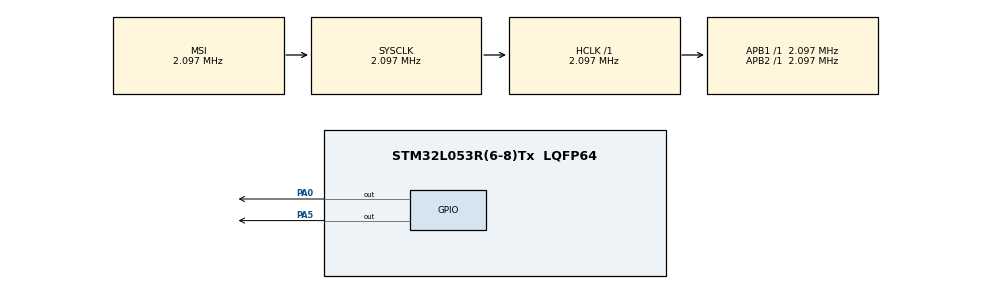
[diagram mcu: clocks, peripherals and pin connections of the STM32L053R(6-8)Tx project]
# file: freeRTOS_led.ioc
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FREERTOS.Tasks01=defaultTask,24,128,StartDefaultTask,Default,NULL,Dynamic,NULL,NULL
Mcu.Family=STM32L0
Mcu.Name=STM32L053R(6-8)Tx
Mcu.Package=LQFP64
PA0.Signal=GPIO_Output
PA5.Signal=GPIO_Output
ProjectManager.HeapSize=0x200
ProjectManager.StackSize=0x400
ProjectManager.TargetToolchain=STM32CubeIDE
RCC.AHBFreq_Value=2097000
RCC.APB1Freq_Value=2097000
RCC.APB1TimFreq_Value=2097000
RCC.APB2Freq_Value=2097000
RCC.APB2TimFreq_Value=2097000
RCC.HSE_VALUE=8000000
RCC.HSI16_VALUE=16000000
RCC.HSI48_VALUE=48000000
RCC.HSI_VALUE=16000000
RCC.LSE_VALUE=32768
RCC.MSI_VALUE=2097000
RCC.SYSCLKFreq_VALUE=2097000
RCC.VCOOutputFreq_Value=48000000
VP_FREERTOS_VS_CMSIS_V2.Mode=CMSIS_V2
board=custom

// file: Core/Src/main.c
/* USER CODE BEGIN Header */
/**
  ******************************************************************************
  * @file           : main.c
  * @brief          : Main program body
  ******************************************************************************
  * @attention
  *
  * Copyright (c) 2023 STMicroelectronics.
  * All rights reserved.
  *
  * This software is licensed under terms that can be found in the LICENSE file
  * in the root directory of this software component.
  * If no LICENSE file comes with this software, it is provided AS-IS.
  *
  ******************************************************************************
  */
/* USER CODE END Header */
#include "main.h"
#include "cmsis_os.h"

/* Definitions for defaultTask */
osThreadId_t defaultTaskHandle;
const osThreadAttr_t defaultTask_attributes = {
  .name = "defaultTask",
  .stack_size = 128 * 4,
  .priority = (osPriority_t) osPriorityNormal,
};

void SystemClock_Config(void);
static void MX_GPIO_Init(void);
void StartDefaultTask(void *argument);

/* USER CODE BEGIN 0 */
__NO_RETURN void thread1(void *arg) {
	while(1) {
		HAL_GPIO_TogglePin(GPIOA, GPIO_PIN_5);
		osDelay(1000);
	}
	osThreadTerminate(NULL);
}

__NO_RETURN void thread2(void *arg) {
	while(1) {
		HAL_GPIO_TogglePin(GPIOA, GPIO_PIN_0);
		osDelay(1000);
	}
	osThreadTerminate(NULL);
}

/* USER CODE END 0 */

int main(void)
{

  /* MCU Configuration--------------------------------------------------------*/

  /* Reset of all peripherals, Initializes the Flash interface and the Systick. */
  HAL_Init();

  /* Configure the system clock */
  SystemClock_Config();

  /* Initialize all configured peripherals */
  MX_GPIO_Init();
  /* USER CODE BEGIN 2 */
  osThreadId_t threadId1;
  threadId1 = osThreadNew(thread1, NULL, NULL);
  osThreadId_t threadId2;
  threadId2 = osThreadNew(thread2, NULL, NULL);

  /* USER CODE END 2 */

  /* Init scheduler */
  osKernelInitialize();

  /* Create the thread(s) */
  /* creation of defaultTask */
  defaultTaskHandle = osThreadNew(StartDefaultTask, NULL, &defaultTask_attributes);

  /* Start scheduler */
  osKernelStart();

  /* We should never get here as control is now taken by the scheduler */
  /* Infinite loop */
  while (1)
  {

  }
}

void SystemClock_Config(void)
{
  RCC_OscInitTypeDef RCC_OscInitStruct = {0};
  RCC_ClkInitTypeDef RCC_ClkInitStruct = {0};

  /** Configure the main internal regulator output voltage
  */
  __HAL_PWR_VOLTAGESCALING_CONFIG(PWR_REGULATOR_VOLTAGE_SCALE1);

  /** Initializes the RCC Oscillators according to the specified parameters
  * in the RCC_OscInitTypeDef structure.
  */
  RCC_OscInitStruct.OscillatorType = RCC_OSCILLATORTYPE_MSI;
  RCC_OscInitStruct.MSIState = RCC_MSI_ON;
  RCC_OscInitStruct.MSICalibrationValue = 0;
  RCC_OscInitStruct.MSIClockRange = RCC_MSIRANGE_5;
  RCC_OscInitStruct.PLL.PLLState = RCC_PLL_NONE;
  if (HAL_RCC_OscConfig(&RCC_OscInitStruct) != HAL_OK)
  {
    Error_Handler();
  }

  /** Initializes the CPU, AHB and APB buses clocks
  */
  RCC_ClkInitStruct.ClockType = RCC_CLOCKTYPE_HCLK|RCC_CLOCKTYPE_SYSCLK
                              |RCC_CLOCKTYPE_PCLK1|RCC_CLOCKTYPE_PCLK2;
  RCC_ClkInitStruct.SYSCLKSource = RCC_SYSCLKSOURCE_MSI;
  RCC_ClkInitStruct.AHBCLKDivider = RCC_SYSCLK_DIV1;
  RCC_ClkInitStruct.APB1CLKDivider = RCC_HCLK_DIV1;
  RCC_ClkInitStruct.APB2CLKDivider = RCC_HCLK_DIV1;

  if (HAL_RCC_ClockConfig(&RCC_ClkInitStruct, FLASH_LATENCY_0) != HAL_OK)
  {
    Error_Handler();
  }
}

static void MX_GPIO_Init(void)
{
  GPIO_InitTypeDef GPIO_InitStruct = {0};

  /* GPIO Ports Clock Enable */
  __HAL_RCC_GPIOA_CLK_ENABLE();

  /*Configure GPIO pin Output Level */
  HAL_GPIO_WritePin(GPIOA, GPIO_PIN_0|GPIO_PIN_5, GPIO_PIN_RESET);

  /*Configure GPIO pins : PA0 PA5 */
  GPIO_InitStruct.Pin = GPIO_PIN_0|GPIO_PIN_5;
  GPIO_InitStruct.Mode = GPIO_MODE_OUTPUT_PP;
  GPIO_InitStruct.Pull = GPIO_NOPULL;
  GPIO_InitStruct.Speed = GPIO_SPEED_FREQ_LOW;
  HAL_GPIO_Init(GPIOA, &GPIO_InitStruct);

}

void StartDefaultTask(void *argument)
{
  for(;;)
  {
    osDelay(1);
  }
}

void Error_Handler(void)
{
  __disable_irq();
  while (1)
  {
  }
}
